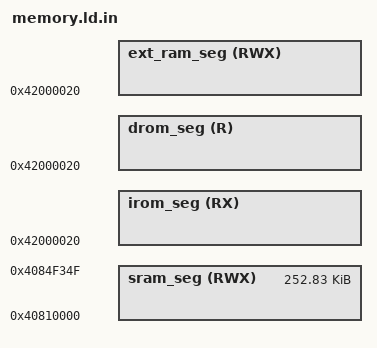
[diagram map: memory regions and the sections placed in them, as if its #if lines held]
/*
 * SPDX-FileCopyrightText: 2025 Espressif Systems (Shanghai) CO LTD
 *
 * SPDX-License-Identifier: Apache-2.0
 */

/* TODO: [ESP32H4] IDF-12305 inherited from verification branch, need check */

/**
 *                    ESP32-H4 Linker Script Memory Layout
 * This file describes the memory layout (memory blocks) by virtual memory addresses.
 * This linker script is passed through the C preprocessor to include configuration options.
 * Please use preprocessor features sparingly!
 * Restrict to simple macros with numeric values, and/or #if/#endif blocks.
 */

#include "sdkconfig.h"
#include "ld.common"

/* TODO: IDF-12517 */
#define SRAM_SEG_START     0x40810000
#define SRAM_SEG_END       0x4084f350  /* 2nd stage bootloader iram_loader_seg start address */
#define SRAM_SEG_SIZE      SRAM_SEG_END - SRAM_SEG_START


#if CONFIG_APP_BUILD_USE_FLASH_SECTIONS
/*
 * IDRAM0_2_SEG_SIZE_DEFAULT is used when page size is 64KB
 */
#define IDRAM0_2_SEG_SIZE   (CONFIG_MMU_PAGE_SIZE << 8)
#endif

MEMORY
{
  /**
   *  All these values assume the flash cache is on, and have the blocks this uses subtracted from the length
   *  of the various regions. The 'data access port' dram/drom regions map to the same iram/irom regions but
   *  are connected to the data port of the CPU and eg allow byte-wise access.
   */

#if CONFIG_APP_BUILD_USE_FLASH_SECTIONS
  /* Flash mapped instruction data */
  irom_seg (RX) :                    org = 0x42000020, len = IDRAM0_2_SEG_SIZE - 0x20

  /**
   * (0x20 offset above is a convenience for the app binary image generation.
   * Flash cache has 64KB pages. The .bin file which is flashed to the chip
   * has a 0x18 byte file header, and each segment has a 0x08 byte segment
   * header. Setting this offset makes it simple to meet the flash cache MMU's
   * constraint that (paddr % 64KB == vaddr % 64KB).)
   */
#endif // CONFIG_APP_BUILD_USE_FLASH_SECTIONS

  /**
   * Shared data RAM, excluding memory reserved for ROM bss/data/stack.
   * Enabling Bluetooth & Trace Memory features in menuconfig will decrease the amount of RAM available.
   */
  sram_seg (RWX) :                   org = SRAM_SEG_START, len = SRAM_SEG_SIZE

#if CONFIG_APP_BUILD_USE_FLASH_SECTIONS
  /* Flash mapped constant data */
  drom_seg (R) :                     org = 0x42000020, len = IDRAM0_2_SEG_SIZE - 0x20

  /* (See irom_seg for meaning of 0x20 offset in the above.) */
#endif // CONFIG_APP_BUILD_USE_FLASH_SECTIONS

  /**
   * `ext_ram_seg` and `drom_seg` / `irom_seg` share the same bus and the address region.
   * A dummy section is used to avoid overlap. See `.ext_ram.dummy` in `sections.ld.in`
   */
  ext_ram_seg(RWX) :           org = 0x42000020, len = IDRAM0_2_SEG_SIZE - 0x20
}

/* Heap ends at top of sram_seg */
_heap_end = 0x40000000;

REGION_ALIAS("iram_text_seg", sram_seg);
REGION_ALIAS("dram_seg", sram_seg);

#if CONFIG_APP_BUILD_USE_FLASH_SECTIONS
  REGION_ALIAS("flash_text_seg", irom_seg);
  REGION_ALIAS("flash_rodata_seg", drom_seg);
#else
  REGION_ALIAS("flash_text_seg", sram_seg);
  REGION_ALIAS("flash_rodata_seg", sram_seg);
#endif // CONFIG_APP_BUILD_USE_FLASH_SECTIONS

ALIGN_VECTOR_TABLE = 0x40;
